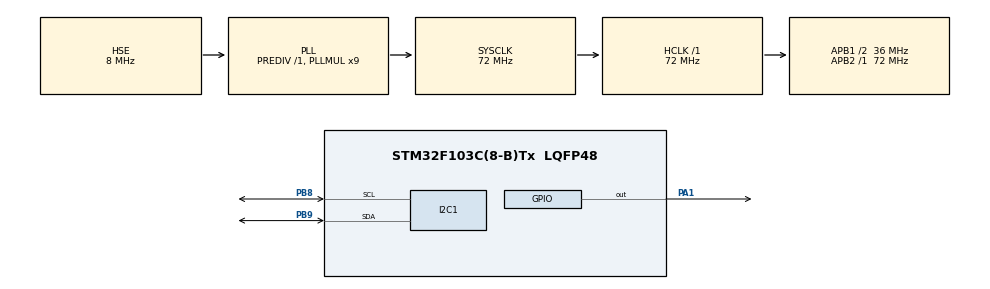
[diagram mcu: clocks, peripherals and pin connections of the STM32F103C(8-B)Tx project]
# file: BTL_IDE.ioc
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Mcu.Family=STM32F1
RCC.PLLSourceVirtual=RCC_PLLSOURCE_HSE
PD1-OSC_OUT.Mode=HSE-External-Oscillator
PD0-OSC_IN.Signal=RCC_OSC_IN
RCC.APB1CLKDivider=RCC_HCLK_DIV2
RCC.SYSCLKSource=RCC_SYSCLKSOURCE_PLLCLK
ProjectManager.StackSize=0x400
PD1-OSC_OUT.Signal=RCC_OSC_OUT
PA13.Signal=SYS_JTMS-SWDIO
TIM1.Prescaler=72-1
ProjectManager.TargetToolchain=STM32CubeIDE
RCC.HCLKFreq_Value=72000000
PB9.Mode=I2C
RCC.APB2TimFreq_Value=72000000
RCC.USBFreq_Value=72000000
PA1.Signal=GPIO_Output
RCC.AHBFreq_Value=72000000
PD0-OSC_IN.Mode=HSE-External-Oscillator
board=custom
RCC.PLLMUL=RCC_PLL_MUL9
RCC.APB2Freq_Value=72000000
PA14.Mode=Serial_Wire
PA13.Mode=Serial_Wire
Mcu.Name=STM32F103C(8-B)Tx
VP_TIM1_VS_ClockSourceINT.Mode=Internal
RCC.SYSCLKFreq_VALUE=72000000
PB9.Signal=I2C1_SDA
Mcu.Package=LQFP48
PA14.Signal=SYS_JTCK-SWCLK
ProjectManager.HeapSize=0x200
NVIC.PriorityGroup=NVIC_PRIORITYGROUP_4
PB8.Mode=I2C
RCC.APB1TimFreq_Value=72000000
PB8.Signal=I2C1_SCL
TIM1.Period=0xffff-1
RCC.APB1Freq_Value=36000000

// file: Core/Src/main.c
/* USER CODE BEGIN Header */
/**
  ******************************************************************************
  * @file           : main.c
  * @brief          : Main program body
  ******************************************************************************
  * @attention
  *
  * <h2><center>&copy; Copyright (c) 2021 STMicroelectronics.
  * All rights reserved.</center></h2>
  *
  * This software component is licensed by ST under BSD 3-Clause license,
  * the "License"; You may not use this file except in compliance with the
  * License. You may obtain a copy of the License at:
  *                        opensource.org/licenses/BSD-3-Clause
  *
  ******************************************************************************
  */
/* USER CODE END Header */
#include "main.h"

/* USER CODE BEGIN Includes */
#include "i2c&lcd.h"
#include "stdio.h"
/* USER CODE END Includes */

I2C_HandleTypeDef hi2c1;

TIM_HandleTypeDef htim1;

void SystemClock_Config(void);
static void MX_GPIO_Init(void);
static void MX_I2C1_Init(void);
static void MX_TIM1_Init(void);

/* USER CODE BEGIN 0 */
void delay(uint16_t us)
{
	__HAL_TIM_SET_COUNTER(&htim1,0);
	while(__HAL_TIM_GET_COUNTER(&htim1)<us);
}
/************************** Display value ***********************************/
void Display_Temp (float Temp)
{
	char str[16] = {0};
    lcd_put_cur(0,0);
    sprintf(str, "TEMP: %.2f ",Temp);
    lcd_send_string(str);
    lcd_send_data('C');
}

void Display_Hmd (float Hmd)
{
	char str[16] = {0};
    lcd_put_cur(1,0);
    sprintf(str, "HMD: %.2f ",Hmd);
    lcd_send_string(str);
  	lcd_send_data('%');
}

/******************************* Declaration ****************************/

uint8_t Hmd_byte1, Hmd_byte2, Temp_byte1, Temp_byte2, SUM;
uint16_t  HMD, TEMP;
float Temperature = 0;
float Humidity = 0;
uint8_t check;

/************************** Set pin *********************************/

void Set_Pin_Output (GPIO_TypeDef *GPIOx, uint16_t GPIO_Pin)
{
	GPIO_InitTypeDef GPIO_InitStruct = {0};
	GPIO_InitStruct.Pin = GPIO_Pin;
	GPIO_InitStruct.Mode = GPIO_MODE_OUTPUT_PP;
	GPIO_InitStruct.Speed = GPIO_SPEED_FREQ_LOW;
	HAL_GPIO_Init(GPIOx, &GPIO_InitStruct);
}

void Set_Pin_Input (GPIO_TypeDef *GPIOx, uint16_t GPIO_Pin)
{
	GPIO_InitTypeDef GPIO_InitStruct = {0};
	GPIO_InitStruct.Pin = GPIO_Pin;
	GPIO_InitStruct.Mode = GPIO_MODE_INPUT;
	GPIO_InitStruct.Pull = GPIO_NOPULL;
	HAL_GPIO_Init(GPIOx, &GPIO_InitStruct);
}

/********************* DHT 11 *************************/

#define DHT11_PORT GPIOA
#define DHT11_PIN GPIO_PIN_1

void DHT11_Start (void)
{
	Set_Pin_Output (DHT11_PORT, DHT11_PIN);  // set the pin as output
	HAL_GPIO_WritePin(DHT11_PORT, DHT11_PIN, 1);// prepare to communicate
	delay(1000);
	HAL_GPIO_WritePin (DHT11_PORT, DHT11_PIN, 0);   // MCU pull down voltage
	delay (18000);   // wait for 18ms
    HAL_GPIO_WritePin (DHT11_PORT, DHT11_PIN, 1);   // MCU pull up voltage
    delay (20);   // wait for 20us
	Set_Pin_Input(DHT11_PORT, DHT11_PIN);    // set as input
}

uint8_t DHT11_Check_Response (void)
{
	uint8_t check = 0;
	delay (40);
	if (!(HAL_GPIO_ReadPin (DHT11_PORT, DHT11_PIN))) // DHT response
	{
		delay (80);
		if ((HAL_GPIO_ReadPin (DHT11_PORT, DHT11_PIN))) check = 1;
		else check = -1;
	}
	while ((HAL_GPIO_ReadPin (DHT11_PORT, DHT11_PIN)));   // wait for the pin to go low

	return check;
}

uint8_t DHT11_Read (void)
{
	uint8_t i,j;
	for (j=0;j<8;j++)
	{
		while (!(HAL_GPIO_ReadPin (DHT11_PORT, DHT11_PIN)));   // wait for the pin to go high
		delay (40);   // wait for 40 us
		if (!(HAL_GPIO_ReadPin (DHT11_PORT, DHT11_PIN)))   // if the pin is low
		{
			i &= ~(1<<(7-j));   // write 0
		}
		else i |= (1<<(7-j));  // write 1
		while ((HAL_GPIO_ReadPin (DHT11_PORT, DHT11_PIN)));  // wait for the pin to go low
	}
	return i;
}

/* USER CODE END 0 */

int main(void)
{

  /* MCU Configuration--------------------------------------------------------*/

  /* Reset of all peripherals, Initializes the Flash interface and the Systick. */
  HAL_Init();

  /* Configure the system clock */
  SystemClock_Config();

  /* Initialize all configured peripherals */
  MX_GPIO_Init();
  MX_I2C1_Init();
  MX_TIM1_Init();
  /* USER CODE BEGIN 2 */
  HAL_TIM_Base_Start(&htim1);

  lcd_init();
  lcd_send_string("Waiting...");
  HAL_Delay(2000);
  lcd_clear();
  /* USER CODE END 2 */

  /* Infinite loop */
  while (1)
  {

    /* USER CODE BEGIN 3 */

	  DHT11_Start();
	  check = DHT11_Check_Response();
	  if (check == 1)
	  {
		  Hmd_byte1 = DHT11_Read();
		  Hmd_byte2 = DHT11_Read();
		  Temp_byte1 = DHT11_Read();
		  Temp_byte2 = DHT11_Read();
		  SUM = DHT11_Read();
		  TEMP = Temp_byte1;
		  HMD = Hmd_byte1;
		  if(SUM != Hmd_byte1 + Hmd_byte2 + Temp_byte1 + Temp_byte2){
			  lcd_put_cur(0,0);
			  lcd_send_string("DHT11 Wrong");
		  }
		  else {
		  Temperature=(float) TEMP;
		  Humidity=(float) HMD;
		  Display_Temp(Temperature);
		  Display_Hmd(Humidity);
		  }
	  }
	  else {
		  lcd_put_cur(0,0);
		  lcd_send_string("Error DHT11");
		  lcd_put_cur(1,0);
		  lcd_send_string("No response");
	  }

	  HAL_Delay(1000);
   }
  /* USER CODE END 3 */
}

void SystemClock_Config(void)
{
  RCC_OscInitTypeDef RCC_OscInitStruct = {0};
  RCC_ClkInitTypeDef RCC_ClkInitStruct = {0};

  /** Initializes the RCC Oscillators according to the specified parameters
  * in the RCC_OscInitTypeDef structure.
  */
  RCC_OscInitStruct.OscillatorType = RCC_OSCILLATORTYPE_HSE;
  RCC_OscInitStruct.HSEState = RCC_HSE_ON;
  RCC_OscInitStruct.HSEPredivValue = RCC_HSE_PREDIV_DIV1;
  RCC_OscInitStruct.HSIState = RCC_HSI_ON;
  RCC_OscInitStruct.PLL.PLLState = RCC_PLL_ON;
  RCC_OscInitStruct.PLL.PLLSource = RCC_PLLSOURCE_HSE;
  RCC_OscInitStruct.PLL.PLLMUL = RCC_PLL_MUL9;
  if (HAL_RCC_OscConfig(&RCC_OscInitStruct) != HAL_OK)
  {
    Error_Handler();
  }
  /** Initializes the CPU, AHB and APB buses clocks
  */
  RCC_ClkInitStruct.ClockType = RCC_CLOCKTYPE_HCLK|RCC_CLOCKTYPE_SYSCLK
                              |RCC_CLOCKTYPE_PCLK1|RCC_CLOCKTYPE_PCLK2;
  RCC_ClkInitStruct.SYSCLKSource = RCC_SYSCLKSOURCE_PLLCLK;
  RCC_ClkInitStruct.AHBCLKDivider = RCC_SYSCLK_DIV1;
  RCC_ClkInitStruct.APB1CLKDivider = RCC_HCLK_DIV2;
  RCC_ClkInitStruct.APB2CLKDivider = RCC_HCLK_DIV1;

  if (HAL_RCC_ClockConfig(&RCC_ClkInitStruct, FLASH_LATENCY_2) != HAL_OK)
  {
    Error_Handler();
  }
}

static void MX_I2C1_Init(void)
{

  hi2c1.Instance = I2C1;
  hi2c1.Init.ClockSpeed = 100000;
  hi2c1.Init.DutyCycle = I2C_DUTYCYCLE_2;
  hi2c1.Init.OwnAddress1 = 0;
  hi2c1.Init.AddressingMode = I2C_ADDRESSINGMODE_7BIT;
  hi2c1.Init.DualAddressMode = I2C_DUALADDRESS_DISABLE;
  hi2c1.Init.OwnAddress2 = 0;
  hi2c1.Init.GeneralCallMode = I2C_GENERALCALL_DISABLE;
  hi2c1.Init.NoStretchMode = I2C_NOSTRETCH_DISABLE;
  if (HAL_I2C_Init(&hi2c1) != HAL_OK)
  {
    Error_Handler();
  }

}

static void MX_TIM1_Init(void)
{

  TIM_ClockConfigTypeDef sClockSourceConfig = {0};
  TIM_MasterConfigTypeDef sMasterConfig = {0};

  htim1.Instance = TIM1;
  htim1.Init.Prescaler = 72-1;
  htim1.Init.CounterMode = TIM_COUNTERMODE_UP;
  htim1.Init.Period = 0xffff-1;
  htim1.Init.ClockDivision = TIM_CLOCKDIVISION_DIV1;
  htim1.Init.RepetitionCounter = 0;
  htim1.Init.AutoReloadPreload = TIM_AUTORELOAD_PRELOAD_DISABLE;
  if (HAL_TIM_Base_Init(&htim1) != HAL_OK)
  {
    Error_Handler();
  }
  sClockSourceConfig.ClockSource = TIM_CLOCKSOURCE_INTERNAL;
  if (HAL_TIM_ConfigClockSource(&htim1, &sClockSourceConfig) != HAL_OK)
  {
    Error_Handler();
  }
  sMasterConfig.MasterOutputTrigger = TIM_TRGO_RESET;
  sMasterConfig.MasterSlaveMode = TIM_MASTERSLAVEMODE_DISABLE;
  if (HAL_TIMEx_MasterConfigSynchronization(&htim1, &sMasterConfig) != HAL_OK)
  {
    Error_Handler();
  }

}

static void MX_GPIO_Init(void)
{
  GPIO_InitTypeDef GPIO_InitStruct = {0};

  /* GPIO Ports Clock Enable */
  __HAL_RCC_GPIOD_CLK_ENABLE();
  __HAL_RCC_GPIOA_CLK_ENABLE();
  __HAL_RCC_GPIOB_CLK_ENABLE();

  /*Configure GPIO pin Output Level */
  HAL_GPIO_WritePin(GPIOA, GPIO_PIN_1, GPIO_PIN_RESET);

  /*Configure GPIO pin : PA1 */
  GPIO_InitStruct.Pin = GPIO_PIN_1;
  GPIO_InitStruct.Mode = GPIO_MODE_OUTPUT_PP;
  GPIO_InitStruct.Pull = GPIO_NOPULL;
  GPIO_InitStruct.Speed = GPIO_SPEED_FREQ_LOW;
  HAL_GPIO_Init(GPIOA, &GPIO_InitStruct);

}

void Error_Handler(void)
{
  __disable_irq();
  while (1)
  {
  }
}

/************************ (C) COPYRIGHT STMicroelectronics *****END OF FILE****/
